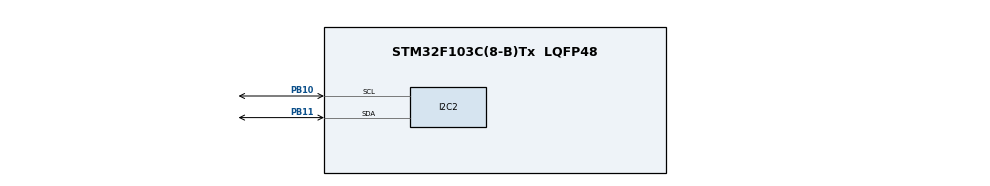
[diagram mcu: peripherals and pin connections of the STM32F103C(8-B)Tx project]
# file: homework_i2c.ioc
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Mcu.Family=STM32F1
Mcu.Name=STM32F103C(8-B)Tx
Mcu.Package=LQFP48
NVIC.I2C2_ER_IRQn=true\:0\:0\:false\:false\:true\:true\:true
NVIC.I2C2_EV_IRQn=true\:0\:0\:false\:false\:true\:true\:true
NVIC.PriorityGroup=NVIC_PRIORITYGROUP_4
PA13.Mode=Serial_Wire
PA13.Signal=SYS_JTMS-SWDIO
PA14.Mode=Serial_Wire
PA14.Signal=SYS_JTCK-SWCLK
PB10.Mode=I2C
PB10.Signal=I2C2_SCL
PB11.Mode=I2C
PB11.Signal=I2C2_SDA
ProjectManager.HeapSize=0x200
ProjectManager.StackSize=0x400
ProjectManager.TargetToolchain=STM32CubeIDE
RCC.APB1Freq_Value=8000000
RCC.APB2Freq_Value=8000000
board=custom

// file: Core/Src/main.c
/* USER CODE BEGIN Header */
/**
 ******************************************************************************
 * @file           : main.c
 * @brief          : Main program body
 ******************************************************************************
 * @attention
 *
 * <h2><center>&copy; Copyright (c) 2021 STMicroelectronics.
 * All rights reserved.</center></h2>
 *
 * This software component is licensed by ST under BSD 3-Clause license,
 * the "License"; You may not use this file except in compliance with the
 * License. You may obtain a copy of the License at:
 *                        opensource.org/licenses/BSD-3-Clause
 *
 ******************************************************************************
 */
/* USER CODE END Header */
#include "main.h"

I2C_HandleTypeDef hi2c2;

/* USER CODE BEGIN PV */
typedef struct {
	uint32_t CRL;
	uint32_t CRH;
	uint32_t IDR;
	uint32_t ODR;

} GPIO_t;
typedef struct {
	uint32_t CR1;
	uint32_t CR2;
	uint32_t OAR1;
	uint32_t OAR2;
	uint32_t DR;
	uint32_t SR1;
	uint32_t SR2;
	uint32_t CCR;
	uint32_t TRIS;
} I2C_t;
GPIO_t *my_gpioB = 0x40010c00;
I2C_t *my_i2c = 0x40005800;
uint32_t data = 0;

void i2c_init() {
	// CLEAR BIT PORT B
	my_gpioB->CRH &= ~(0b1111 << 8) | (0b1111 << 12);
	// SET GPIO PIN B10 B11 Alternate function open drain
	my_gpioB->CRH |= (0b1111 << 8) | (0b1111 << 12);
	// DISABLE PERIPHERAL PORT B
	my_i2c->CR1 &= ~(0b1);
	while (((my_i2c->SR2 >> 1) & 1) == 1) {
		my_i2c->CR1 |= (1 << 15);
		my_i2c->CR1 &= ~(1 << 15);
	}
	// SET SCL CLOCK
	my_i2c->CCR = 0x28;
	// SET I2C PERIPHERAL CLOCK
	my_i2c->CR2 |= 8;
	// ENABLE I2C
	my_i2c->CR1 |= (0b1);
	// ENABLE ACK
	//my_i2c->CR1 |= (1 << 10);
}
void i2c_write() {
	int temp;
	// START
	my_i2c->CR1 |= (1 << 8);
	// WAIT SB SET
	while ((my_i2c->SR1 & 1) != 1)
		;
	// SEND 7 BIT ADDRESS
	my_i2c->DR = (0b1010000 << 1) | 0;
	// WAIT ADDR SET
	while (((my_i2c->SR1 >> 1) & 1) != 1)
		;
	// CLEAR ADDR
	temp = my_i2c->SR1;
	temp = my_i2c->SR2;
	// WAIT TX iS SET
	while (((my_i2c->SR1 >> 7) & 1) != 1)
		;
	// WIRTE ADDRESS VARIABLE
	my_i2c->DR = 0x08;
	// WAIT DATA SEND
	while (((my_i2c->SR1 >> 7) & 1) != 1)
		;
	// WRITE VALUE
	my_i2c->DR = 1;
	// WAIT DATA SEND
	while (((my_i2c->SR1 >> 7) & 1) != 1)
		;
	// STOP
	my_i2c->CR1 |= (0b1 << 9);
}
void i2c_read() {
	int temp;
	// START
	my_i2c->CR1 |= (1 << 8);
	// WAIT SB SET
	while ((my_i2c->SR1 & 1) != 1)
		;
	// SEND 7 BIT ADDRESS
	my_i2c->DR = (0b1010000 << 1) | 0;
	// WAIT ADDR SET
	while (((my_i2c->SR1 >> 1) & 1) != 1)
		;
	// CLEAR ADDR
	temp = my_i2c->SR2;
	// WAIT TX iS SET
	while (((my_i2c->SR1 >> 7) & 1) != 1)
		;
	// WIRTE ADDRESS VARIABLE
	my_i2c->DR = 0x08;
	// WAIT DATA SEND
	while (((my_i2c->SR1 >> 7) & 1) != 1)
		;
	// STOP
	my_i2c->CR1 |= (0b1 << 9);

	// START
	my_i2c->CR1 |= (1 << 8);
	// WAIT SB SET
	while ((my_i2c->SR1 & 1) != 1)
		;

	//SEND 7 BIT ADDRESS
	my_i2c->DR = (0b1010000 << 1) | 1;

	// WAIT ADDR SET
	while (((my_i2c->SR1 >> 1) & 1) != 1)
		;
	// CLEAR ADDR
	temp = my_i2c->SR2;

	while ((((my_i2c->SR1 >> 6) & 1) != 1))
		;
	// READ DATA
	data = my_i2c->DR;
	// STOP
	my_i2c->CR1 |= (0b1 << 9);

}
/* USER CODE END PV */

void SystemClock_Config(void);
static void MX_GPIO_Init(void);
static void MX_I2C2_Init(void);

int main(void) {

	/* MCU Configuration--------------------------------------------------------*/

	/* Reset of all peripherals, Initializes the Flash interface and the Systick. */
	HAL_Init();

	/* Configure the system clock */
	SystemClock_Config();

	/* Initialize all configured peripherals */
	MX_GPIO_Init();
	MX_I2C2_Init();
	/* USER CODE BEGIN 2 */
	__HAL_RCC_GPIOB_CLK_ENABLE();
	__HAL_RCC_AFIO_CLK_ENABLE();
	__HAL_RCC_I2C2_CLK_ENABLE();
	i2c_init();
	i2c_write();
	i2c_read();
	/* USER CODE END 2 */

	/* Infinite loop */
	while (1) {

	}
}

void SystemClock_Config(void) {
	RCC_OscInitTypeDef RCC_OscInitStruct = { 0 };
	RCC_ClkInitTypeDef RCC_ClkInitStruct = { 0 };

	/** Initializes the RCC Oscillators according to the specified parameters
	 * in the RCC_OscInitTypeDef structure.
	 */
	RCC_OscInitStruct.OscillatorType = RCC_OSCILLATORTYPE_HSI;
	RCC_OscInitStruct.HSIState = RCC_HSI_ON;
	RCC_OscInitStruct.HSICalibrationValue = RCC_HSICALIBRATION_DEFAULT;
	RCC_OscInitStruct.PLL.PLLState = RCC_PLL_NONE;
	if (HAL_RCC_OscConfig(&RCC_OscInitStruct) != HAL_OK) {
		Error_Handler();
	}
	/** Initializes the CPU, AHB and APB buses clocks
	 */
	RCC_ClkInitStruct.ClockType = RCC_CLOCKTYPE_HCLK | RCC_CLOCKTYPE_SYSCLK
			| RCC_CLOCKTYPE_PCLK1 | RCC_CLOCKTYPE_PCLK2;
	RCC_ClkInitStruct.SYSCLKSource = RCC_SYSCLKSOURCE_HSI;
	RCC_ClkInitStruct.AHBCLKDivider = RCC_SYSCLK_DIV1;
	RCC_ClkInitStruct.APB1CLKDivider = RCC_HCLK_DIV1;
	RCC_ClkInitStruct.APB2CLKDivider = RCC_HCLK_DIV1;

	if (HAL_RCC_ClockConfig(&RCC_ClkInitStruct, FLASH_LATENCY_0) != HAL_OK) {
		Error_Handler();
	}
}

static void MX_I2C2_Init(void) {

	hi2c2.Instance = I2C2;
	hi2c2.Init.ClockSpeed = 100000;
	hi2c2.Init.DutyCycle = I2C_DUTYCYCLE_2;
	hi2c2.Init.OwnAddress1 = 0;
	hi2c2.Init.AddressingMode = I2C_ADDRESSINGMODE_7BIT;
	hi2c2.Init.DualAddressMode = I2C_DUALADDRESS_DISABLE;
	hi2c2.Init.OwnAddress2 = 0;
	hi2c2.Init.GeneralCallMode = I2C_GENERALCALL_DISABLE;
	hi2c2.Init.NoStretchMode = I2C_NOSTRETCH_DISABLE;
	if (HAL_I2C_Init(&hi2c2) != HAL_OK) {
		Error_Handler();
	}

}

static void MX_GPIO_Init(void) {

	/* GPIO Ports Clock Enable */
	__HAL_RCC_GPIOB_CLK_ENABLE();
	__HAL_RCC_GPIOA_CLK_ENABLE();

}

void Error_Handler(void) {
	__disable_irq();
	while (1) {
	}
}

/************************ (C) COPYRIGHT STMicroelectronics *****END OF FILE****/
